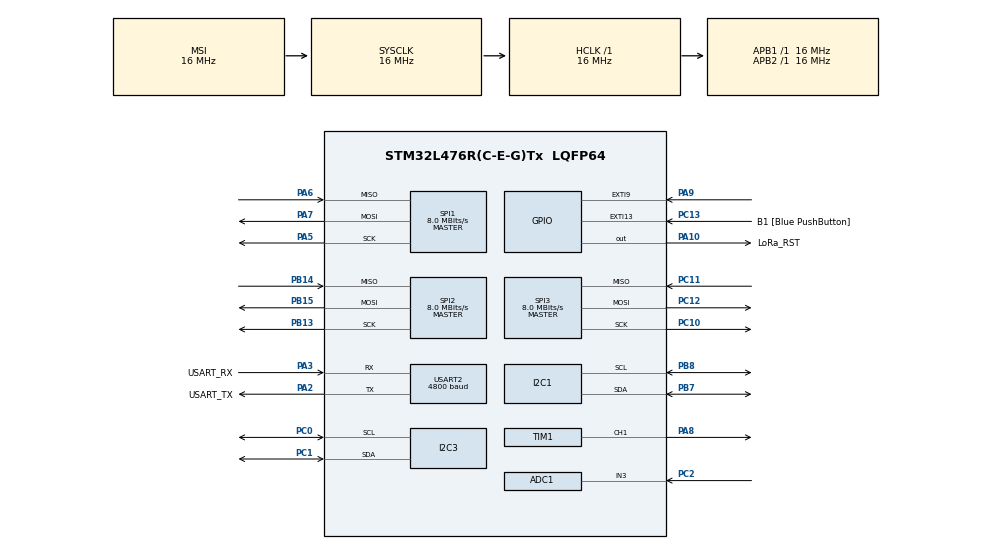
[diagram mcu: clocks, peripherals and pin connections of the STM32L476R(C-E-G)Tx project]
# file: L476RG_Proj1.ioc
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ADC1.Channel-1\#ChannelRegularConversion=ADC_CHANNEL_3
ADC1.ClockPrescaler=ADC_CLOCK_SYNC_PCLK_DIV4
ADC1.ContinuousConvMode=ENABLE
ADC1.EnableAnalogWatchDog1=true
ADC1.LowPowerAutoWait=ENABLE
ADC1.NbrOfConversion=1
ADC1.NbrOfConversionFlag=1
ADC1.OffsetNumber-1\#ChannelRegularConversion=ADC_OFFSET_NONE
ADC1.Overrun=ADC_OVR_DATA_OVERWRITTEN
ADC1.Rank-1\#ChannelRegularConversion=1
ADC1.Resolution=ADC_RESOLUTION_8B
ADC1.SamplingTime-1\#ChannelRegularConversion=ADC_SAMPLETIME_2CYCLES_5
ADC1.WatchdogChannel=ADC_CHANNEL_3
ADC1.master=1
Dma.Request0=USART2_RX
Dma.Request1=USART2_TX
Dma.USART2_RX.0.Direction=DMA_PERIPH_TO_MEMORY
Dma.USART2_RX.0.Instance=DMA1_Channel6
Dma.USART2_RX.0.MemDataAlignment=DMA_MDATAALIGN_BYTE
Dma.USART2_RX.0.MemInc=DMA_MINC_ENABLE
Dma.USART2_RX.0.Mode=DMA_NORMAL
Dma.USART2_RX.0.PeriphDataAlignment=DMA_PDATAALIGN_BYTE
Dma.USART2_RX.0.PeriphInc=DMA_PINC_DISABLE
Dma.USART2_RX.0.Priority=DMA_PRIORITY_MEDIUM
Dma.USART2_TX.1.Direction=DMA_MEMORY_TO_PERIPH
Dma.USART2_TX.1.Instance=DMA1_Channel7
Dma.USART2_TX.1.MemDataAlignment=DMA_MDATAALIGN_BYTE
Dma.USART2_TX.1.MemInc=DMA_MINC_ENABLE
Dma.USART2_TX.1.Mode=DMA_NORMAL
Dma.USART2_TX.1.PeriphDataAlignment=DMA_PDATAALIGN_BYTE
Dma.USART2_TX.1.PeriphInc=DMA_PINC_DISABLE
Dma.USART2_TX.1.Priority=DMA_PRIORITY_MEDIUM
I2C1.Timing=0x00303D5B
I2C3.Timing=0x00303D5B
Mcu.Family=STM32L4
Mcu.Name=STM32L476R(C-E-G)Tx
Mcu.Package=LQFP64
NVIC.ADC1_2_IRQn=true\:2\:0\:true\:false\:true\:false\:true\:true\:true
NVIC.DMA1_Channel6_IRQn=true\:0\:0\:false\:false\:true\:false\:false\:true\:true
NVIC.DMA1_Channel7_IRQn=true\:0\:0\:false\:false\:true\:false\:false\:true\:true
NVIC.EXTI9_5_IRQn=true\:2\:0\:true\:true\:true\:1\:false\:true\:true\:true
NVIC.PVD_PVM_IRQn=true\:0\:0\:false\:false\:true\:false\:true\:true\:true
NVIC.PriorityGroup=NVIC_PRIORITYGROUP_2
NVIC.TIM1_CC_IRQn=true\:2\:0\:true\:false\:true\:false\:true\:true\:true
NVIC.TIM1_UP_TIM16_IRQn=true\:2\:0\:true\:false\:true\:false\:true\:true\:true
NVIC.TIM6_DAC_IRQn=true\:3\:0\:false\:false\:true\:false\:false\:true\:true
NVIC.TimeBase=TIM6_DAC_IRQn
NVIC.TimeBaseIP=TIM6
NVIC.USART2_IRQn=true\:0\:0\:false\:false\:true\:false\:true\:true\:true
PA10.GPIO_Label=LoRa_RST
PA10.Signal=GPIO_Output
PA13\ (JTMS-SWDIO).GPIO_Label=TMS
PA13\ (JTMS-SWDIO).Mode=JTAG_4_pins
PA13\ (JTMS-SWDIO).Signal=SYS_JTMS-SWDIO
PA14\ (JTCK-SWCLK).GPIO_Label=TCK
PA14\ (JTCK-SWCLK).Mode=JTAG_4_pins
PA14\ (JTCK-SWCLK).Signal=SYS_JTCK-SWCLK
PA15\ (JTDI).Mode=JTAG_4_pins
PA15\ (JTDI).Signal=SYS_JTDI
PA2.GPIO_Label=USART_TX
PA2.GPIO_Mode=GPIO_MODE_AF_PP
PA2.GPIO_PuPd=GPIO_NOPULL
PA2.GPIO_Speed=GPIO_SPEED_FREQ_VERY_HIGH
PA2.Mode=Asynchronous
PA2.Signal=USART2_TX
PA3.GPIO_Label=USART_RX
PA3.GPIO_Mode=GPIO_MODE_AF_PP
PA3.GPIO_PuPd=GPIO_NOPULL
PA3.GPIO_Speed=GPIO_SPEED_FREQ_VERY_HIGH
PA3.Mode=Asynchronous
PA3.Signal=USART2_RX
PA5.Mode=Full_Duplex_Master
PA5.Signal=SPI1_SCK
PA6.Mode=Full_Duplex_Master
PA6.Signal=SPI1_MISO
PA7.Mode=Full_Duplex_Master
PA7.Signal=SPI1_MOSI
PA8.Signal=S_TIM1_CH1
PA9.Signal=GPXTI9
PB13.Mode=Full_Duplex_Master
PB13.Signal=SPI2_SCK
PB14.Mode=Full_Duplex_Master
PB14.Signal=SPI2_MISO
PB15.Mode=Full_Duplex_Master
PB15.Signal=SPI2_MOSI
PB3\ (JTDO-TRACESWO).GPIO_Label=SWO
PB3\ (JTDO-TRACESWO).Mode=JTAG_4_pins
PB3\ (JTDO-TRACESWO).Signal=SYS_JTDO-SWO
PB7.GPIO_Pu=GPIO_NOPULL
PB7.Mode=I2C
PB7.Signal=I2C1_SDA
PB8.GPIO_Pu=GPIO_NOPULL
PB8.Mode=I2C
PB8.Signal=I2C1_SCL
PC0.GPIO_Pu=GPIO_NOPULL
PC0.Mode=I2C
PC0.Signal=I2C3_SCL
PC1.GPIO_Pu=GPIO_NOPULL
PC1.Mode=I2C
PC1.Signal=I2C3_SDA
PC10.Mode=Full_Duplex_Master
PC10.Signal=SPI3_SCK
PC11.Mode=Full_Duplex_Master
PC11.Signal=SPI3_MISO
PC12.Mode=Full_Duplex_Master
PC12.Signal=SPI3_MOSI
PC13.GPIO_Label=B1 [Blue PushButton]
PC13.GPIO_ModeDefaultEXTI=GPIO_MODE_IT_FALLING
PC13.GPIO_PuPd=GPIO_NOPULL
PC13.Signal=GPXTI13
PC14-OSC32_IN\ (PC14).Signal=RCC_OSC32_IN
PC15-OSC32_OUT\ (PC15).Signal=RCC_OSC32_OUT
PC2.Signal=ADCx_IN3
PC5.Mode=SYS_WakeUp4
PC5.Signal=SYS_WKUP5
PH0-OSC_IN\ (PH0).Signal=RCC_OSC_IN
PH1-OSC_OUT\ (PH1).Signal=RCC_OSC_OUT
ProjectManager.HeapSize=0x200
ProjectManager.StackSize=0x400
ProjectManager.TargetToolchain=STM32CubeIDE
RCC.ADCCLockSelection=RCC_ADCCLKSOURCE_SYSCLK
RCC.ADCFreq_Value=16000000
RCC.AHBFreq_Value=16000000
RCC.APB1Freq_Value=16000000
RCC.APB1TimFreq_Value=16000000
RCC.APB2Freq_Value=16000000
RCC.APB2TimFreq_Value=16000000
RCC.CortexFreq_Value=16000000
RCC.HCLKFreq_Value=16000000
RCC.HSE_VALUE=8000000
RCC.HSI_VALUE=16000000
RCC.LSE_VALUE=32768
RCC.MSIClockRange=RCC_MSIRANGE_8
RCC.MSI_VALUE=16000000
RCC.PLLN=10
RCC.PLLSourceVirtual=RCC_PLLSOURCE_HSI
RCC.PWR_Regulator_Voltage_Scale=PWR_REGULATOR_VOLTAGE_SCALE2
RCC.SYSCLKFreq_VALUE=16000000
RCC.USART2CLockSelection=RCC_USART2CLKSOURCE_SYSCLK
RCC.USBFreq_Value=64000000
RCC.VCOOutputFreq_Value=160000000
SH.ADCx_IN3.0=ADC1_IN3,IN3-Single-Ended
SH.S_TIM1_CH1.0=TIM1_CH1,Output Compare1 CH1
SPI1.BaudRatePrescaler=SPI_BAUDRATEPRESCALER_2
SPI1.CalculateBaudRate=8.0 MBits/s
SPI1.Direction=SPI_DIRECTION_2LINES
SPI1.Mode=SPI_MODE_MASTER
SPI1.VirtualType=VM_MASTER
SPI2.CalculateBaudRate=8.0 MBits/s
SPI2.Direction=SPI_DIRECTION_2LINES
SPI2.Mode=SPI_MODE_MASTER
SPI2.VirtualType=VM_MASTER
SPI3.CalculateBaudRate=8.0 MBits/s
SPI3.Direction=SPI_DIRECTION_2LINES
SPI3.Mode=SPI_MODE_MASTER
SPI3.VirtualType=VM_MASTER
STMicroelectronics.X-CUBE-AZRTOS-L4.2.0.0.TX_APP_CREATION=1
STMicroelectronics.X-CUBE-AZRTOS-L4.2.0.0.TX_APP_GENERATE_INIT_CODE=false
STMicroelectronics.X-CUBE-AZRTOS-L4.2.0.0.TX_APP_MEM_POOL_SIZE=16384
STMicroelectronics.X-CUBE-AZRTOS-L4.2.0.0.TX_APP_MSG_QUEUE_CREATION=1
STMicroelectronics.X-CUBE-AZRTOS-L4.2.0.0.TX_APP_MUTEX_CREATION=1
STMicroelectronics.X-CUBE-AZRTOS-L4.2.0.0.TX_APP_SEM_CREATION=1
STMicroelectronics.X-CUBE-AZRTOS-L4.2.0.0.TX_BASEPRI_SUPPORT=1
STMicroelectronics.X-CUBE-AZRTOS-L4.2.0.0.TX_DISABLE_ERROR_CHECKING=0
STMicroelectronics.X-CUBE-AZRTOS-L4.2.0.0.TX_DISABLE_NOTIFY_CALLBACKS=0
STMicroelectronics.X-CUBE-AZRTOS-L4.2.0.0.TX_DISABLE_PREEMPTION_THRESHOLD=0
STMicroelectronics.X-CUBE-AZRTOS-L4.2.0.0.TX_ENABLE_STACK_CHECKING=1
STMicroelectronics.X-CUBE-AZRTOS-L4.2.0.0.TX_Mutex_INHERITANCE=TX_INHERIT
STMicroelectronics.X-CUBE-AZRTOS-L4.2.0.0.TX_SEMAPHORE_COUNT=1
STMicroelectronics.X-CUBE-AZRTOS-L4.2.0.0.TX_TIMER_THREAD_STACK_SIZE=2048
STMicroelectronics.X-CUBE-AZRTOS-L4.2.0.0.TX_TIMER_TICKS_PER_SECOND=1000
STMicroelectronics.X-CUBE-AZRTOS-L4.2.0.0.ThreadXCcRTOSJjThreadXJjCore=true
STMicroelectronics.X-CUBE-AZRTOS-L4.2.0.0_IsAnAzureRtosMw=true
SYS.Mode=PWR_PVD_MODE_IT_RISING
TIM1.Channel-Output\ Compare1\ CH1=TIM_CHANNEL_1
USART2.BaudRate=4800
USART2.VirtualMode-Asynchronous=VM_ASYNC
VP_CRC_VS_CRC.Mode=CRC_Activate
VP_LPTIM1_VS_LPTIM_counterModeInternalClock.Mode=Counts__internal_clock_event_00
VP_STMicroelectronics.X-CUBE-AZRTOS-L4_VS_RTOSJjThreadX_6.2.0_2.0.0.Mode=RTOSJjThreadX
VP_SYS_VS_tim6.Mode=TIM6
VP_SYS_V_PVD_IN.Mode=Mode_PVD_Int
VP_TIM1_VS_ClockSourceINT.Mode=Internal
VP_TIM2_VS_ClockSourceINT.Mode=Internal
board=NUCLEO-L476RG

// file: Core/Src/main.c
/* USER CODE BEGIN Header */
/**
  ******************************************************************************
  * @file           : main.c
  * @brief          : Main program body
  ******************************************************************************
  * @attention
  *
  * Copyright (c) 2024 STMicroelectronics.
  * All rights reserved.
  *
  * This software is licensed under terms that can be found in the LICENSE file
  * in the root directory of this software component.
  * If no LICENSE file comes with this software, it is provided AS-IS.
  *
  ******************************************************************************
  */
/* USER CODE END Header */
#include "main.h"
#include "app_threadx.h"

ADC_HandleTypeDef hadc1;

CRC_HandleTypeDef hcrc;

I2C_HandleTypeDef hi2c1;
I2C_HandleTypeDef hi2c3;

LPTIM_HandleTypeDef hlptim1;

SPI_HandleTypeDef hspi1;
SPI_HandleTypeDef hspi2;
SPI_HandleTypeDef hspi3;

TIM_HandleTypeDef htim1;
TIM_HandleTypeDef htim2;

UART_HandleTypeDef huart2;
DMA_HandleTypeDef hdma_usart2_rx;
DMA_HandleTypeDef hdma_usart2_tx;

void SystemClock_Config(void);
static void MX_GPIO_Init(void);
static void MX_DMA_Init(void);
static void MX_SPI1_Init(void);
static void MX_ADC1_Init(void);
static void MX_CRC_Init(void);
static void MX_I2C1_Init(void);
static void MX_I2C3_Init(void);
static void MX_LPTIM1_Init(void);
static void MX_SPI2_Init(void);
static void MX_SPI3_Init(void);
static void MX_TIM1_Init(void);
static void MX_TIM2_Init(void);
static void MX_USART2_UART_Init(void);
static void MX_NVIC_Init(void);

int main(void)
{

  /* MCU Configuration--------------------------------------------------------*/

  /* Reset of all peripherals, Initializes the Flash interface and the Systick. */
  HAL_Init();

  /* Configure the system clock */
  SystemClock_Config();

  /* Initialize all configured peripherals */
  MX_GPIO_Init();
  MX_DMA_Init();
  MX_SPI1_Init();
  MX_ADC1_Init();
  MX_CRC_Init();
  MX_I2C1_Init();
  MX_I2C3_Init();
  MX_LPTIM1_Init();
  MX_SPI2_Init();
  MX_SPI3_Init();
  MX_TIM1_Init();
  MX_TIM2_Init();
  MX_USART2_UART_Init();

  /* Initialize interrupts */
  MX_NVIC_Init();

  MX_ThreadX_Init();
  /* Infinite loop */
  /* USER CODE BEGIN WHILE */

  // PUT SYSTEM INITS HERE, SINCE DEPEND ON THREADX
  while (1)
  {
    /* USER CODE END WHILE */

  }
}

void SystemClock_Config(void)
{
  RCC_OscInitTypeDef RCC_OscInitStruct = {0};
  RCC_ClkInitTypeDef RCC_ClkInitStruct = {0};

  /** Configure the main internal regulator output voltage
  */
  if (HAL_PWREx_ControlVoltageScaling(PWR_REGULATOR_VOLTAGE_SCALE2) != HAL_OK)
  {
    Error_Handler();
  }
  /** Initializes the RCC Oscillators according to the specified parameters
  * in the RCC_OscInitTypeDef structure.
  */
  RCC_OscInitStruct.OscillatorType = RCC_OSCILLATORTYPE_MSI;
  RCC_OscInitStruct.MSIState = RCC_MSI_ON;
  RCC_OscInitStruct.MSICalibrationValue = 0;
  RCC_OscInitStruct.MSIClockRange = RCC_MSIRANGE_8;
  RCC_OscInitStruct.PLL.PLLState = RCC_PLL_NONE;
  if (HAL_RCC_OscConfig(&RCC_OscInitStruct) != HAL_OK)
  {
    Error_Handler();
  }
  /** Initializes the CPU, AHB and APB buses clocks
  */
  RCC_ClkInitStruct.ClockType = RCC_CLOCKTYPE_HCLK|RCC_CLOCKTYPE_SYSCLK
                              |RCC_CLOCKTYPE_PCLK1|RCC_CLOCKTYPE_PCLK2;
  RCC_ClkInitStruct.SYSCLKSource = RCC_SYSCLKSOURCE_MSI;
  RCC_ClkInitStruct.AHBCLKDivider = RCC_SYSCLK_DIV1;
  RCC_ClkInitStruct.APB1CLKDivider = RCC_HCLK_DIV1;
  RCC_ClkInitStruct.APB2CLKDivider = RCC_HCLK_DIV1;

  if (HAL_RCC_ClockConfig(&RCC_ClkInitStruct, FLASH_LATENCY_2) != HAL_OK)
  {
    Error_Handler();
  }
}

/**
  * @brief NVIC Configuration.
  * @retval None
  */
static void MX_NVIC_Init(void)
{
  /* EXTI9_5_IRQn interrupt configuration */
  HAL_NVIC_SetPriority(EXTI9_5_IRQn, 2, 0);
  HAL_NVIC_EnableIRQ(EXTI9_5_IRQn);
}

static void MX_ADC1_Init(void)
{

  ADC_MultiModeTypeDef multimode = {0};
  ADC_AnalogWDGConfTypeDef AnalogWDGConfig = {0};
  ADC_ChannelConfTypeDef sConfig = {0};

  /** Common config
  */
  hadc1.Instance = ADC1;
  hadc1.Init.ClockPrescaler = ADC_CLOCK_SYNC_PCLK_DIV4;
  hadc1.Init.Resolution = ADC_RESOLUTION_8B;
  hadc1.Init.DataAlign = ADC_DATAALIGN_RIGHT;
  hadc1.Init.ScanConvMode = ADC_SCAN_DISABLE;
  hadc1.Init.EOCSelection = ADC_EOC_SINGLE_CONV;
  hadc1.Init.LowPowerAutoWait = ENABLE;
  hadc1.Init.ContinuousConvMode = ENABLE;
  hadc1.Init.NbrOfConversion = 1;
  hadc1.Init.DiscontinuousConvMode = DISABLE;
  hadc1.Init.ExternalTrigConv = ADC_SOFTWARE_START;
  hadc1.Init.ExternalTrigConvEdge = ADC_EXTERNALTRIGCONVEDGE_NONE;
  hadc1.Init.DMAContinuousRequests = DISABLE;
  hadc1.Init.Overrun = ADC_OVR_DATA_OVERWRITTEN;
  hadc1.Init.OversamplingMode = DISABLE;
  if (HAL_ADC_Init(&hadc1) != HAL_OK)
  {
    Error_Handler();
  }
  /** Configure the ADC multi-mode
  */
  multimode.Mode = ADC_MODE_INDEPENDENT;
  if (HAL_ADCEx_MultiModeConfigChannel(&hadc1, &multimode) != HAL_OK)
  {
    Error_Handler();
  }
  /** Configure Analog WatchDog 1
  */
  AnalogWDGConfig.WatchdogNumber = ADC_ANALOGWATCHDOG_1;
  AnalogWDGConfig.WatchdogMode = ADC_ANALOGWATCHDOG_SINGLE_REG;
  AnalogWDGConfig.Channel = ADC_CHANNEL_3;
  AnalogWDGConfig.ITMode = DISABLE;
  AnalogWDGConfig.HighThreshold = 0;
  AnalogWDGConfig.LowThreshold = 0;
  if (HAL_ADC_AnalogWDGConfig(&hadc1, &AnalogWDGConfig) != HAL_OK)
  {
    Error_Handler();
  }
  /** Configure Regular Channel
  */
  sConfig.Channel = ADC_CHANNEL_3;
  sConfig.Rank = ADC_REGULAR_RANK_1;
  sConfig.SamplingTime = ADC_SAMPLETIME_2CYCLES_5;
  sConfig.SingleDiff = ADC_SINGLE_ENDED;
  sConfig.OffsetNumber = ADC_OFFSET_NONE;
  sConfig.Offset = 0;
  if (HAL_ADC_ConfigChannel(&hadc1, &sConfig) != HAL_OK)
  {
    Error_Handler();
  }

}

static void MX_CRC_Init(void)
{

  hcrc.Instance = CRC;
  hcrc.Init.DefaultPolynomialUse = DEFAULT_POLYNOMIAL_ENABLE;
  hcrc.Init.DefaultInitValueUse = DEFAULT_INIT_VALUE_ENABLE;
  hcrc.Init.InputDataInversionMode = CRC_INPUTDATA_INVERSION_NONE;
  hcrc.Init.OutputDataInversionMode = CRC_OUTPUTDATA_INVERSION_DISABLE;
  hcrc.InputDataFormat = CRC_INPUTDATA_FORMAT_BYTES;
  if (HAL_CRC_Init(&hcrc) != HAL_OK)
  {
    Error_Handler();
  }

}

static void MX_I2C1_Init(void)
{

  hi2c1.Instance = I2C1;
  hi2c1.Init.Timing = 0x00303D5B;
  hi2c1.Init.OwnAddress1 = 0;
  hi2c1.Init.AddressingMode = I2C_ADDRESSINGMODE_7BIT;
  hi2c1.Init.DualAddressMode = I2C_DUALADDRESS_DISABLE;
  hi2c1.Init.OwnAddress2 = 0;
  hi2c1.Init.OwnAddress2Masks = I2C_OA2_NOMASK;
  hi2c1.Init.GeneralCallMode = I2C_GENERALCALL_DISABLE;
  hi2c1.Init.NoStretchMode = I2C_NOSTRETCH_DISABLE;
  if (HAL_I2C_Init(&hi2c1) != HAL_OK)
  {
    Error_Handler();
  }
  /** Configure Analogue filter
  */
  if (HAL_I2CEx_ConfigAnalogFilter(&hi2c1, I2C_ANALOGFILTER_ENABLE) != HAL_OK)
  {
    Error_Handler();
  }
  /** Configure Digital filter
  */
  if (HAL_I2CEx_ConfigDigitalFilter(&hi2c1, 0) != HAL_OK)
  {
    Error_Handler();
  }

}

static void MX_I2C3_Init(void)
{

  hi2c3.Instance = I2C3;
  hi2c3.Init.Timing = 0x00303D5B;
  hi2c3.Init.OwnAddress1 = 0;
  hi2c3.Init.AddressingMode = I2C_ADDRESSINGMODE_7BIT;
  hi2c3.Init.DualAddressMode = I2C_DUALADDRESS_DISABLE;
  hi2c3.Init.OwnAddress2 = 0;
  hi2c3.Init.OwnAddress2Masks = I2C_OA2_NOMASK;
  hi2c3.Init.GeneralCallMode = I2C_GENERALCALL_DISABLE;
  hi2c3.Init.NoStretchMode = I2C_NOSTRETCH_DISABLE;
  if (HAL_I2C_Init(&hi2c3) != HAL_OK)
  {
    Error_Handler();
  }
  /** Configure Analogue filter
  */
  if (HAL_I2CEx_ConfigAnalogFilter(&hi2c3, I2C_ANALOGFILTER_ENABLE) != HAL_OK)
  {
    Error_Handler();
  }
  /** Configure Digital filter
  */
  if (HAL_I2CEx_ConfigDigitalFilter(&hi2c3, 0) != HAL_OK)
  {
    Error_Handler();
  }

}

static void MX_LPTIM1_Init(void)
{

  hlptim1.Instance = LPTIM1;
  hlptim1.Init.Clock.Source = LPTIM_CLOCKSOURCE_APBCLOCK_LPOSC;
  hlptim1.Init.Clock.Prescaler = LPTIM_PRESCALER_DIV1;
  hlptim1.Init.Trigger.Source = LPTIM_TRIGSOURCE_SOFTWARE;
  hlptim1.Init.OutputPolarity = LPTIM_OUTPUTPOLARITY_HIGH;
  hlptim1.Init.UpdateMode = LPTIM_UPDATE_IMMEDIATE;
  hlptim1.Init.CounterSource = LPTIM_COUNTERSOURCE_INTERNAL;
  hlptim1.Init.Input1Source = LPTIM_INPUT1SOURCE_GPIO;
  hlptim1.Init.Input2Source = LPTIM_INPUT2SOURCE_GPIO;
  if (HAL_LPTIM_Init(&hlptim1) != HAL_OK)
  {
    Error_Handler();
  }

}

static void MX_SPI1_Init(void)
{

  /* SPI1 parameter configuration*/
  hspi1.Instance = SPI1;
  hspi1.Init.Mode = SPI_MODE_MASTER;
  hspi1.Init.Direction = SPI_DIRECTION_2LINES;
  hspi1.Init.DataSize = SPI_DATASIZE_4BIT;
  hspi1.Init.CLKPolarity = SPI_POLARITY_LOW;
  hspi1.Init.CLKPhase = SPI_PHASE_1EDGE;
  hspi1.Init.NSS = SPI_NSS_SOFT;
  hspi1.Init.BaudRatePrescaler = SPI_BAUDRATEPRESCALER_2;
  hspi1.Init.FirstBit = SPI_FIRSTBIT_MSB;
  hspi1.Init.TIMode = SPI_TIMODE_DISABLE;
  hspi1.Init.CRCCalculation = SPI_CRCCALCULATION_DISABLE;
  hspi1.Init.CRCPolynomial = 7;
  hspi1.Init.CRCLength = SPI_CRC_LENGTH_DATASIZE;
  hspi1.Init.NSSPMode = SPI_NSS_PULSE_ENABLE;
  if (HAL_SPI_Init(&hspi1) != HAL_OK)
  {
    Error_Handler();
  }

}

static void MX_SPI2_Init(void)
{

  /* SPI2 parameter configuration*/
  hspi2.Instance = SPI2;
  hspi2.Init.Mode = SPI_MODE_MASTER;
  hspi2.Init.Direction = SPI_DIRECTION_2LINES;
  hspi2.Init.DataSize = SPI_DATASIZE_4BIT;
  hspi2.Init.CLKPolarity = SPI_POLARITY_LOW;
  hspi2.Init.CLKPhase = SPI_PHASE_1EDGE;
  hspi2.Init.NSS = SPI_NSS_SOFT;
  hspi2.Init.BaudRatePrescaler = SPI_BAUDRATEPRESCALER_2;
  hspi2.Init.FirstBit = SPI_FIRSTBIT_MSB;
  hspi2.Init.TIMode = SPI_TIMODE_DISABLE;
  hspi2.Init.CRCCalculation = SPI_CRCCALCULATION_DISABLE;
  hspi2.Init.CRCPolynomial = 7;
  hspi2.Init.CRCLength = SPI_CRC_LENGTH_DATASIZE;
  hspi2.Init.NSSPMode = SPI_NSS_PULSE_ENABLE;
  if (HAL_SPI_Init(&hspi2) != HAL_OK)
  {
    Error_Handler();
  }

}

static void MX_SPI3_Init(void)
{

  /* SPI3 parameter configuration*/
  hspi3.Instance = SPI3;
  hspi3.Init.Mode = SPI_MODE_MASTER;
  hspi3.Init.Direction = SPI_DIRECTION_2LINES;
  hspi3.Init.DataSize = SPI_DATASIZE_4BIT;
  hspi3.Init.CLKPolarity = SPI_POLARITY_LOW;
  hspi3.Init.CLKPhase = SPI_PHASE_1EDGE;
  hspi3.Init.NSS = SPI_NSS_SOFT;
  hspi3.Init.BaudRatePrescaler = SPI_BAUDRATEPRESCALER_2;
  hspi3.Init.FirstBit = SPI_FIRSTBIT_MSB;
  hspi3.Init.TIMode = SPI_TIMODE_DISABLE;
  hspi3.Init.CRCCalculation = SPI_CRCCALCULATION_DISABLE;
  hspi3.Init.CRCPolynomial = 7;
  hspi3.Init.CRCLength = SPI_CRC_LENGTH_DATASIZE;
  hspi3.Init.NSSPMode = SPI_NSS_PULSE_ENABLE;
  if (HAL_SPI_Init(&hspi3) != HAL_OK)
  {
    Error_Handler();
  }

}

static void MX_TIM1_Init(void)
{

  TIM_ClockConfigTypeDef sClockSourceConfig = {0};
  TIM_MasterConfigTypeDef sMasterConfig = {0};
  TIM_OC_InitTypeDef sConfigOC = {0};
  TIM_BreakDeadTimeConfigTypeDef sBreakDeadTimeConfig = {0};

  htim1.Instance = TIM1;
  htim1.Init.Prescaler = 0;
  htim1.Init.CounterMode = TIM_COUNTERMODE_UP;
  htim1.Init.Period = 65535;
  htim1.Init.ClockDivision = TIM_CLOCKDIVISION_DIV1;
  htim1.Init.RepetitionCounter = 0;
  htim1.Init.AutoReloadPreload = TIM_AUTORELOAD_PRELOAD_DISABLE;
  if (HAL_TIM_Base_Init(&htim1) != HAL_OK)
  {
    Error_Handler();
  }
  sClockSourceConfig.ClockSource = TIM_CLOCKSOURCE_INTERNAL;
  if (HAL_TIM_ConfigClockSource(&htim1, &sClockSourceConfig) != HAL_OK)
  {
    Error_Handler();
  }
  if (HAL_TIM_OC_Init(&htim1) != HAL_OK)
  {
    Error_Handler();
  }
  sMasterConfig.MasterOutputTrigger = TIM_TRGO_RESET;
  sMasterConfig.MasterOutputTrigger2 = TIM_TRGO2_RESET;
  sMasterConfig.MasterSlaveMode = TIM_MASTERSLAVEMODE_DISABLE;
  if (HAL_TIMEx_MasterConfigSynchronization(&htim1, &sMasterConfig) != HAL_OK)
  {
    Error_Handler();
  }
  sConfigOC.OCMode = TIM_OCMODE_TIMING;
  sConfigOC.Pulse = 0;
  sConfigOC.OCPolarity = TIM_OCPOLARITY_HIGH;
  sConfigOC.OCNPolarity = TIM_OCNPOLARITY_HIGH;
  sConfigOC.OCFastMode = TIM_OCFAST_DISABLE;
  sConfigOC.OCIdleState = TIM_OCIDLESTATE_RESET;
  sConfigOC.OCNIdleState = TIM_OCNIDLESTATE_RESET;
  if (HAL_TIM_OC_ConfigChannel(&htim1, &sConfigOC, TIM_CHANNEL_1) != HAL_OK)
  {
    Error_Handler();
  }
  sBreakDeadTimeConfig.OffStateRunMode = TIM_OSSR_DISABLE;
  sBreakDeadTimeConfig.OffStateIDLEMode = TIM_OSSI_DISABLE;
  sBreakDeadTimeConfig.LockLevel = TIM_LOCKLEVEL_OFF;
  sBreakDeadTimeConfig.DeadTime = 0;
  sBreakDeadTimeConfig.BreakState = TIM_BREAK_DISABLE;
  sBreakDeadTimeConfig.BreakPolarity = TIM_BREAKPOLARITY_HIGH;
  sBreakDeadTimeConfig.BreakFilter = 0;
  sBreakDeadTimeConfig.Break2State = TIM_BREAK2_DISABLE;
  sBreakDeadTimeConfig.Break2Polarity = TIM_BREAK2POLARITY_HIGH;
  sBreakDeadTimeConfig.Break2Filter = 0;
  sBreakDeadTimeConfig.AutomaticOutput = TIM_AUTOMATICOUTPUT_DISABLE;
  if (HAL_TIMEx_ConfigBreakDeadTime(&htim1, &sBreakDeadTimeConfig) != HAL_OK)
  {
    Error_Handler();
  }
  HAL_TIM_MspPostInit(&htim1);

}

static void MX_TIM2_Init(void)
{

  TIM_ClockConfigTypeDef sClockSourceConfig = {0};
  TIM_MasterConfigTypeDef sMasterConfig = {0};

  htim2.Instance = TIM2;
  htim2.Init.Prescaler = 0;
  htim2.Init.CounterMode = TIM_COUNTERMODE_UP;
  htim2.Init.Period = 4294967295;
  htim2.Init.ClockDivision = TIM_CLOCKDIVISION_DIV1;
  htim2.Init.AutoReloadPreload = TIM_AUTORELOAD_PRELOAD_DISABLE;
  if (HAL_TIM_Base_Init(&htim2) != HAL_OK)
  {
    Error_Handler();
  }
  sClockSourceConfig.ClockSource = TIM_CLOCKSOURCE_INTERNAL;
  if (HAL_TIM_ConfigClockSource(&htim2, &sClockSourceConfig) != HAL_OK)
  {
    Error_Handler();
  }
  sMasterConfig.MasterOutputTrigger = TIM_TRGO_RESET;
  sMasterConfig.MasterSlaveMode = TIM_MASTERSLAVEMODE_DISABLE;
  if (HAL_TIMEx_MasterConfigSynchronization(&htim2, &sMasterConfig) != HAL_OK)
  {
    Error_Handler();
  }

}

static void MX_USART2_UART_Init(void)
{

  huart2.Instance = USART2;
  huart2.Init.BaudRate = 4800;
  huart2.Init.WordLength = UART_WORDLENGTH_8B;
  huart2.Init.StopBits = UART_STOPBITS_1;
  huart2.Init.Parity = UART_PARITY_NONE;
  huart2.Init.Mode = UART_MODE_TX_RX;
  huart2.Init.HwFlowCtl = UART_HWCONTROL_NONE;
  huart2.Init.OverSampling = UART_OVERSAMPLING_16;
  huart2.Init.OneBitSampling = UART_ONE_BIT_SAMPLE_DISABLE;
  huart2.AdvancedInit.AdvFeatureInit = UART_ADVFEATURE_NO_INIT;
  if (HAL_UART_Init(&huart2) != HAL_OK)
  {
    Error_Handler();
  }

}

static void MX_DMA_Init(void)
{

  /* DMA controller clock enable */
  __HAL_RCC_DMA1_CLK_ENABLE();

  /* DMA interrupt init */
  /* DMA1_Channel6_IRQn interrupt configuration */
  HAL_NVIC_SetPriority(DMA1_Channel6_IRQn, 0, 0);
  HAL_NVIC_EnableIRQ(DMA1_Channel6_IRQn);
  /* DMA1_Channel7_IRQn interrupt configuration */
  HAL_NVIC_SetPriority(DMA1_Channel7_IRQn, 0, 0);
  HAL_NVIC_EnableIRQ(DMA1_Channel7_IRQn);

}

static void MX_GPIO_Init(void)
{
  GPIO_InitTypeDef GPIO_InitStruct = {0};

  /* GPIO Ports Clock Enable */
  __HAL_RCC_GPIOC_CLK_ENABLE();
  __HAL_RCC_GPIOH_CLK_ENABLE();
  __HAL_RCC_GPIOA_CLK_ENABLE();
  __HAL_RCC_GPIOB_CLK_ENABLE();

  /*Configure GPIO pin Output Level */
  HAL_GPIO_WritePin(LoRa_RST_GPIO_Port, LoRa_RST_Pin, GPIO_PIN_RESET);

  /*Configure GPIO pin : B1_Pin */
  GPIO_InitStruct.Pin = B1_Pin;
  GPIO_InitStruct.Mode = GPIO_MODE_IT_FALLING;
  GPIO_InitStruct.Pull = GPIO_NOPULL;
  HAL_GPIO_Init(B1_GPIO_Port, &GPIO_InitStruct);

  /*Configure GPIO pin : PA9 */
  GPIO_InitStruct.Pin = GPIO_PIN_9;
  GPIO_InitStruct.Mode = GPIO_MODE_IT_RISING;
  GPIO_InitStruct.Pull = GPIO_NOPULL;
  HAL_GPIO_Init(GPIOA, &GPIO_InitStruct);

  /*Configure GPIO pin : LoRa_RST_Pin */
  GPIO_InitStruct.Pin = LoRa_RST_Pin;
  GPIO_InitStruct.Mode = GPIO_MODE_OUTPUT_PP;
  GPIO_InitStruct.Pull = GPIO_NOPULL;
  GPIO_InitStruct.Speed = GPIO_SPEED_FREQ_LOW;
  HAL_GPIO_Init(LoRa_RST_GPIO_Port, &GPIO_InitStruct);

}

void HAL_TIM_PeriodElapsedCallback(TIM_HandleTypeDef *htim)
{
  if (htim->Instance == TIM6) {
    HAL_IncTick();
  }
}

void Error_Handler(void)
{
  __disable_irq();
  while (1)
  {
  }
}
